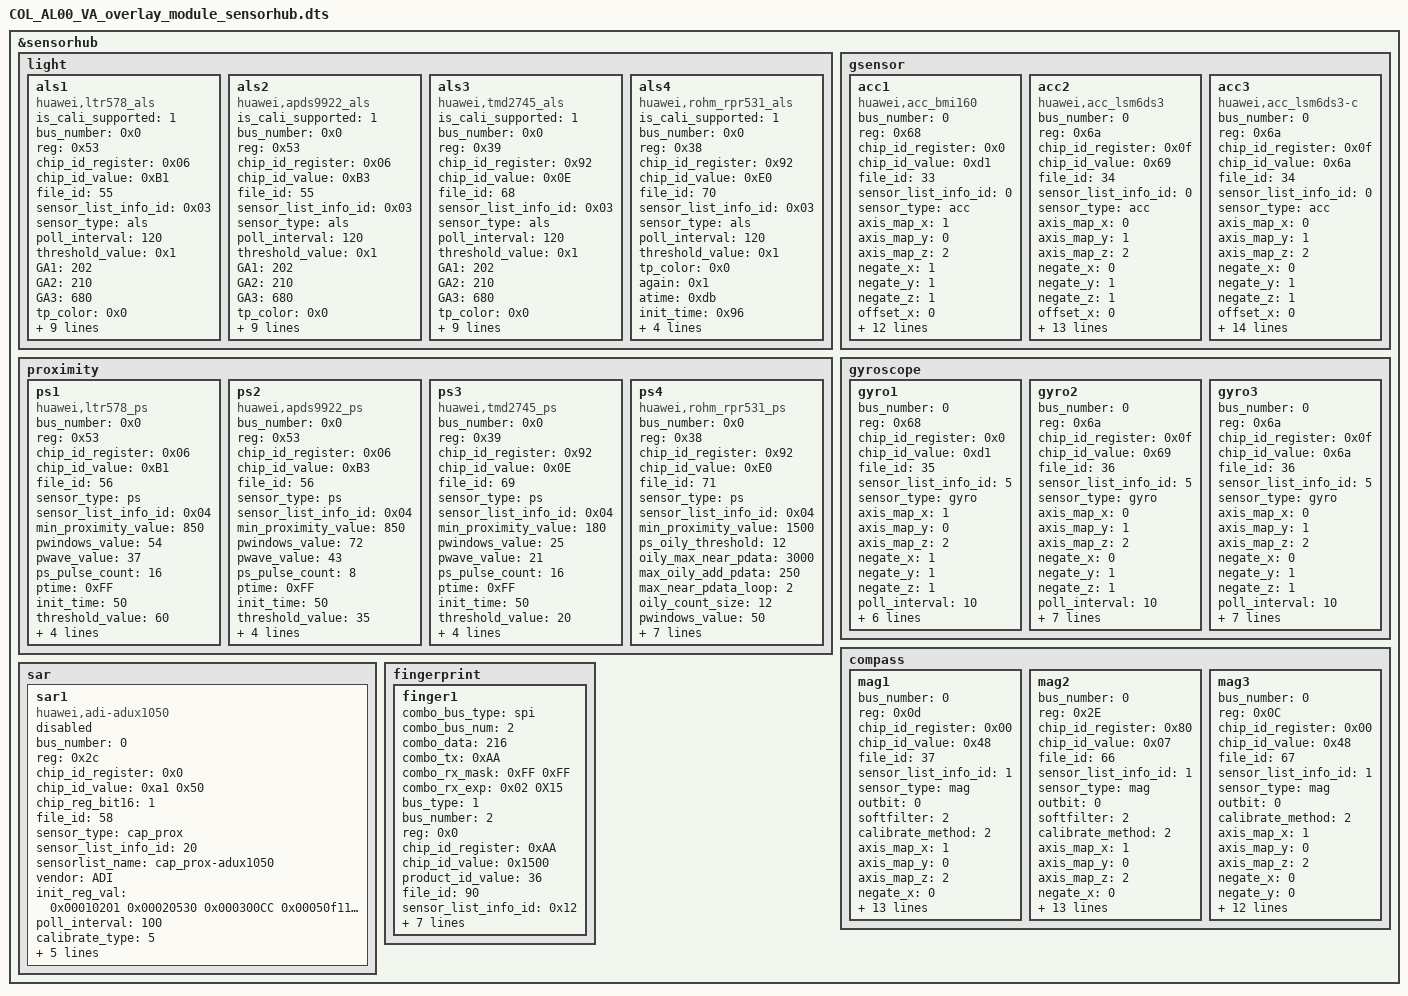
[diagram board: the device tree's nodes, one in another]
&sensorhub{
		light{
			als1{
				is_cali_supported = <1>;
				compatible="huawei,ltr578_als";
				bus_number = <0x0>;
				reg=<0x53>;
				chip_id_register = <0x06>;
				chip_id_value = <0xB1>;
				file_id = <55>;
				sensor_list_info_id = <0x03>;
				sensor_type = "als";
				poll_interval = <120>;
				threshold_value = <0x1>;
				GA1 = <202>;
				GA2 = <210>;
				GA3 = <680>;
				tp_color = <0x0>;
				again = <0x1>;
				atime = <0xdb>;
				init_time = <0x96>;
				status = "ok";
				als_phone_type = <35>;
				als_phone_version = <11>;
				als_extend_data = <10 0x0 0x0 0x0 0x0 0x0 0x0 0x0 0x0 0x0 0x0 0x0>;
				sensorlist_name="light-ltr578";
				vendor="liteon";
			};
			als2{
				is_cali_supported = <1>;
				compatible="huawei,apds9922_als";
				bus_number = <0x0>;
				reg=<0x53>;
				chip_id_register = <0x06>;
				chip_id_value = <0xB3>;
				file_id = <55>;
				sensor_list_info_id = <0x03>;
				sensor_type = "als";
				poll_interval = <120>;
				threshold_value = <0x1>;
				GA1 = <202>;
				GA2 = <210>;
				GA3 = <680>;
				tp_color = <0x0>;
				again = <0x1>;
				atime = <0xdb>;
				init_time = <0x96>;
				status = "ok";
				als_phone_type = <35>;
				als_phone_version = <11>;
				als_extend_data = <4 0x0 0x0 0x0 0x0 0x0 0x0 0x0 0x0 0x0 0x0 0x0>;
				sensorlist_name="light-apds9922";
				vendor="avago";
			};
			als3{
				is_cali_supported = <1>;
				compatible="huawei,tmd2745_als";
				bus_number = <0x0>;
				reg=<0x39>;
				chip_id_register = <0x92>;
				chip_id_value = <0x0E>;
				file_id = <68>;
				sensor_list_info_id = <0x03>;
				sensor_type = "als";
				poll_interval = <120>;
				threshold_value = <0x1>;
				GA1 = <202>;
				GA2 = <210>;
				GA3 = <680>;
				tp_color = <0x0>;
				again = <16>;
				atime = <0x64>;
				init_time = <0x96>;
				status = "ok";
				als_phone_type = <35>;
				als_phone_version = <11>;
				als_extend_data = <4 0x0 0x0 0x0 0x0 0x0 0x0 0x0 0x0 0x0 0x0 0x0>;
				sensorlist_name="light-tmd2745";
				vendor="ams";
			};
			als4{
				is_cali_supported = <1>;
				compatible="huawei,rohm_rpr531_als";
				bus_number = <0x0>;
				reg = <0x38>;   /*iic slave address*/
				chip_id_register = <0x92>;/*manufact_id reg*/
				chip_id_value = <0xE0>;  /*manufact reg content */
				file_id = <70>;
				sensor_list_info_id = <0x03>;
				sensor_type = "als";
				poll_interval = <120>;
				threshold_value = <0x1>;
				tp_color = <0x0>;
				again = <0x1>;
				atime = <0xdb>;
				init_time = <0x96>;
				status = "ok";
				als_phone_type = <35>;
				als_phone_version = <11>;
				als_extend_data = <10843 9754 3779 1810 6417 5571 1629 580 1000 1520 2300 3100>;
			};
		};

		proximity{
			ps1{
				compatible="huawei,ltr578_ps";
				bus_number = <0x0>;
				reg = <0x53>;
				chip_id_register = <0x06>;
				chip_id_value = <0xB1>;
				file_id = <56>;
				sensor_type = "ps";
				sensor_list_info_id = <0x04>;
				min_proximity_value = <850>;
				pwindows_value = <54>;
				pwave_value = <37>;
				ps_pulse_count=<16>;
				ptime=<0xFF>;
				init_time = <50>;
				status = "ok";
				threshold_value = <60>;
				/*gpio_int1 = <&gpio27 1 0>;*/
				poll_interval = <100>;
				use_oily_judge = <1>;/*1 mean use,0 mean dont use*/
				sensorlist_name="proximity-ltr578";
				vendor="liteon";
			};
			ps2{
				compatible="huawei,apds9922_ps";
				bus_number = <0x0>;
				reg = <0x53>;
				chip_id_register = <0x06>;
				chip_id_value = <0xB3>;
				file_id = <56>;
				sensor_type = "ps";
				sensor_list_info_id = <0x04>;
				min_proximity_value = <850>;
				pwindows_value = <72>;
				pwave_value = <43>;
				ps_pulse_count=<8>;
				ptime=<0xFF>;
				init_time = <50>;
				status = "ok";
				threshold_value = <35>;
				/*gpio_int1 = <&gpio27 1 0>;*/
				poll_interval = <100>;
				use_oily_judge = <1>;/*1 mean use,0 mean dont use*/
				sensorlist_name="proximity-apds9922";
				vendor="avago";
			};
			ps3{
				compatible="huawei,tmd2745_ps";
				bus_number = <0x0>;
				reg = <0x39>;
				chip_id_register = <0x92>;
				chip_id_value = <0x0E>;
				file_id = <69>;
				sensor_type = "ps";
				sensor_list_info_id = <0x04>;
				min_proximity_value = <180>;
				pwindows_value = <25>;
				pwave_value = <21>;
				ps_pulse_count=<16>;
				ptime=<0xFF>;
				init_time = <50>;
				status = "ok";
				threshold_value = <20>;
				/*gpio_int1 = <&gpio27 1 0>;*/
				poll_interval = <100>;
				use_oily_judge = <1>;/*1 mean use,0 mean dont use*/
				sensorlist_name="proximity-tmd2745";
				vendor="ams";
			};
			ps4{
				compatible="huawei,rohm_rpr531_ps";
				bus_number = <0x0>;
				reg = <0x38>;   /*iic slave address*/
				chip_id_register = <0x92>;/*manufact_id reg*/
				chip_id_value = <0xE0>;  /*manufact reg content */
				file_id = <71>;
				sensor_type = "ps";
				sensor_list_info_id = <0x04>;
				min_proximity_value = <1500>;
				ps_oily_threshold = <12>;
				oily_max_near_pdata = <3000>;
				max_oily_add_pdata = <250>;
				max_near_pdata_loop = <2>;
				oily_count_size = <12>;
				pwindows_value = <50>;
				pwave_value = <29>;
				ps_pulse_count=<0x8>;
				ptime=<0xFF>;
				init_time = <50>;
				status = "ok";
				threshold_value = <27>;
				/*gpio_int1 = <&gpio27 1 0>;*/
				poll_interval = <100>;
				use_oily_judge = <1>;/*1 mean use,0 mean dont use*/
			};
		};
		gsensor {
			acc1{
				compatible="huawei,acc_bmi160";
				bus_number =<0>;
				reg=<0x68>;
				chip_id_register=<0x0>;
				chip_id_value=<0xd1>;
				file_id=<33>;
				sensor_list_info_id =<0>;
				sensor_type ="acc";
				axis_map_x =<1>;
				axis_map_y =<0>;
				axis_map_z =<2>;
				negate_x =<1>;
				negate_y =<1>;
				negate_z =<1>;
				offset_x =<0>;
				offset_y =<0>;
				offset_z =<0>;
				minDelay=<4000>;
				sensitivity_x =<1>;
				sensitivity_y =<1>;
				sensitivity_z =<1>;
				gpio_int1 =<&gpio26 0 0>;
				gpio_int2=<&gpio25 7 0>;
				gpio_int2_sh=<1010>;
				calibrate_style =<0>;
				sensorlist_name="accelerometer-bmi160";
				vendor="bosch";
				status = "ok";
			};
			acc2{
				compatible="huawei,acc_lsm6ds3";
				bus_number =<0>;
				reg=<0x6a>;
				chip_id_register=<0x0f>;
				chip_id_value=<0x69>;
				file_id=<34>;
				sensor_list_info_id =<0>;
				sensor_type ="acc";
				axis_map_x =<0>;
				axis_map_y =<1>;
				axis_map_z =<2>;
				negate_x =<0>;
				negate_y =<1>;
				negate_z =<1>;
				offset_x =<0>;
				offset_y =<0>;
				offset_z =<0>;
				sensitivity_x =<1>;
				sensitivity_y =<1>;
				sensitivity_z =<1>;
				poll_interval =<10>;
				minDelay=<4000>;
				gpio_int1 =<&gpio26 0 0>;
				gpio_int2=<&gpio25 7 0>;
				gpio_int2_sh=<1010>;
				device_type=<0>;/* */
				calibrate_style =<0>;
				sensorlist_name="accelerometer-lsm6ds3";
				vendor="st";
				status = "ok";
			};
			acc3{
				compatible="huawei,acc_lsm6ds3-c";
				bus_number =<0>;
				reg=<0x6a>;
				chip_id_register=<0x0f>;
				chip_id_value=<0x6a>;
				file_id=<34>;
				sensor_list_info_id =<0>;
				sensor_type ="acc";
				axis_map_x =<0>;
				axis_map_y =<1>;
				axis_map_z =<2>;
				negate_x =<0>;
				negate_y =<1>;
				negate_z =<1>;
				offset_x =<0>;
				offset_y =<0>;
				offset_z =<0>;
				sensitivity_x =<1>;
				sensitivity_y =<1>;
				sensitivity_z =<1>;
				poll_interval =<10>;
				minDelay=<4000>;
				gpio_int1 =<&gpio26 0 0>;
				gpio_int2=<&gpio25 7 0>;
				device_type=<1>;
				gpio_int2_sh=<1010>;
				calibrate_style =<0>;
				wakeup_duration =<0x20>;/*set up 1 duration*/
				sensorlist_name="accelerometer-lsm6ds3-c";
				vendor="st";
				status = "ok";
			};
		};

		gyroscope {
			gyro1{
				bus_number =<0>;
				reg=<0x68>;
				chip_id_register=<0x0>;
				chip_id_value=<0xd1>;
				file_id=<35>;
				sensor_list_info_id =<5>;
				sensor_type ="gyro";
				axis_map_x =<1>;
				axis_map_y =<0>;
				axis_map_z =<2>;
				negate_x =<1>;
				negate_y =<1>;
				negate_z =<1>;
				poll_interval =<10>;
				gpio_int1 =<&gpio26 2 0>;
				gpio_int2=<&gpio25 7 0>;
				gpio_int2_sh=<1010>;
				minDelay=<4000>;
				sensorlist_name="gyroscope-bmi160";
				vendor="bosch";
				status = "ok";
			};
			gyro2{
				bus_number =<0>;
				reg=<0x6a>;
				chip_id_register=<0x0f>;
				chip_id_value=<0x69>;
				file_id=<36>;
				sensor_list_info_id =<5>;
				sensor_type ="gyro";
				/*sensor-vdd-supply = <&ldo24>;*/
				axis_map_x =<0>;
				axis_map_y =<1>;
				axis_map_z =<2>;
				negate_x =<0>;
				negate_y =<1>;
				negate_z =<1>;
				poll_interval =<10>;
				gpio_int1 =<&gpio26 2 0>;
				gpio_int2=<&gpio25 7 0>;
				gpio_int2_sh=<1010>;
				minDelay=<4000>;
				still_calibrate_threshold=<20>;
				sensorlist_name="gyroscope-lsm6ds3";
				vendor="st";
				status = "ok";
			};
			gyro3{
				bus_number =<0>;
				reg=<0x6a>;
				chip_id_register=<0x0f>;
				chip_id_value=<0x6a>;
				file_id=<36>;
				sensor_list_info_id =<5>;
				sensor_type ="gyro";
				/*sensor-vdd-supply = <&ldo24>;*/
				axis_map_x =<0>;
				axis_map_y =<1>;
				axis_map_z =<2>;
				negate_x =<0>;
				negate_y =<1>;
				negate_z =<1>;
				poll_interval =<10>;
				gpio_int1 =<&gpio26 2 0>;
				gpio_int2=<&gpio25 7 0>;
				gpio_int2_sh=<1010>;
				minDelay=<4000>;
				still_calibrate_threshold =<20>;
				sensorlist_name="gyroscope-lsm6ds3-c";
				vendor="st";
				status = "ok";
			};

		};
		compass{
			mag1{
				bus_number=<0>;
				reg=<0x0d>;
				chip_id_register=<0x00>;
				chip_id_value=<0x48>;
				file_id=<37>;
				sensor_list_info_id=<1>;
				sensor_type="mag";
				/*sensor-vdd-supply = <&ldo24>;*/
				outbit=<0>;
				softfilter = <2>;
				calibrate_method=<2>;
				axis_map_x=<1>;
				axis_map_y=<0>;
				axis_map_z=<2>;
				negate_x=<0>;
				negate_y=<0>;
				negate_z=<1>;
				poll_interval=<10>;
				gpio_int1=<&gpio0 0 0>;
				gpio_reset=<&gpio0 0 0>;
				softiron_parameter = <184 40 59 255 168 255 119 0 173 39 142 255 79 1 153 0 69 38  0 0 0 0 0 0 0 0 0>;
				sensorlist_name="mag-akm09911";
				vendor="akm";
				minDelay=<10000>;
				fifoReservedEventCount=<0>;
				fifoMaxEventCount=<0>;
				threshold_for_als_calibrate=<3500>;
				status = "ok";
			};
			mag2{
				bus_number=<0>;
				reg=<0x2E>;
				chip_id_register=<0x80>;
				chip_id_value=<0x07>;
				file_id=<66>;
				sensor_list_info_id=<1>;
				sensor_type="mag";
				/*sensor-vdd-supply = <&ldo24>;*/
				outbit=<0>;
				softfilter = <2>;
				calibrate_method=<2>;
				axis_map_x=<1>;
				axis_map_y=<0>;
				axis_map_z=<2>;
				negate_x=<0>;
				negate_y=<0>;
				negate_z=<1>;
				poll_interval=<10>;
				gpio_int1=<&gpio0 0 0>;
				gpio_reset=<&gpio0 0 0>;
				softiron_parameter = <16 39 0 0 0 0 0 0 16 39 0 0 0 0 0 0 16 39 0 0 0 0 0 0 0 0 0>;
				sensorlist_name="mag-yas537";
				vendor="yamaha";
				minDelay=<10000>;
				fifoReservedEventCount=<0>;
				fifoMaxEventCount=<0>;
				threshold_for_als_calibrate=<2000>;
				status = "ok";
			};
			mag3{
				bus_number=<0>;
				reg=<0x0C>;
				chip_id_register=<0x00>;
				chip_id_value=<0x48>;
				file_id=<67>;
				sensor_list_info_id=<1>;
				sensor_type="mag";
				/*sensor-vdd-supply = <&ldo24>;*/
				outbit=<0>;
				calibrate_method=<2>;
				axis_map_x=<1>;
				axis_map_y=<0>;
				axis_map_z=<2>;
				negate_x=<0>;
				negate_y=<0>;
				negate_z=<1>;
				poll_interval=<10>;
				gpio_int1=<&gpio0 0 0>;
				gpio_reset=<&gpio0 0 0>;
				softiron_parameter = <184 40 59 255 168 255 119 0 173 39 142 255 79 1 153 0 69 38  0 0 0 0 0 0 0 0 0>;
				sensorlist_name="akm-akm09918";
				vendor="akm";
				minDelay=<10000>;
				fifoReservedEventCount=<0>;
				fifoMaxEventCount=<0>;
				threshold_for_als_calibrate=<3500>;
				status = "ok";
			};
		};

		sar{
			sar1{
				compatible="huawei,adi-adux1050";
				bus_number=<0>;
				reg=<0x2c>;
				chip_id_register=<0x0>;
				chip_id_value=<0xa1 0x50>;
				chip_reg_bit16=<1>;
				file_id=<58>;
				sensor_type="cap_prox";
				sensor_list_info_id=<20>;
				/*sensor-vdd-supply = <&ldo24>;*/
				sensorlist_name="cap_prox-adux1050";
				vendor="ADI";
				init_reg_val = <0x00010201 0x00020530 0x000300CC 0x00050f11 0x00063952 0x00070308 0x00080200 0x00090079
				0x000A0005 0x00798000 0x00000000 0x00000000 0x00000000 0x00000000 0x00000000 0x0000000A>;
				poll_interval=<100>;
				calibrate_type=<5>;
				calibrate_order = "0";  // 0:free  1:near  2:far  3:other
				to_ap_threshold = /bits/ 16 <0xC8 0x00 0x00>;
				to_modem_threshold = /bits/ 16 <30000  5000   3000   1700    300    200    0x0000 0x0000
				                                0x0000 0x0000 0x0000 0x0000 0x0000 0x0000 0x0000 0x0000
				                                0x0000 0x0000 0x0000 0x0000 0x0000 0x0000 0x0000 0x0000>;
				shared_flag=<0>;
				status = "disabled";
			};
		};

		fingerprint{
			finger1{
				combo_bus_type = "spi";
				combo_bus_num = <2>;
				combo_data = <216>;
				combo_tx = /bits/ 8 <0xAA>;
				combo_rx_mask = /bits/ 8 <0xFF 0xFF>;
				combo_rx_exp = /bits/ 8 <0x02 0X15>;

				bus_type=<1>;
				bus_number=<2>;
				reg=<0x0>;
				chip_id_register=<0xAA>;
				chip_id_value=<0x1500>;
				product_id_value=<36>;
				file_id=<90>;
				sensor_list_info_id = <0x12>;
				sensor_type ="fingerprint";
				poll_interval = <500>;
				gpio_irq = <211>;
				gpio_irq_sh = <1014>;
				gpio_reset = <210>;
				gpio_reset_sh = <1013>;
				gpio_cs = <216>;
				status = "ok";
			};
		};
	};
